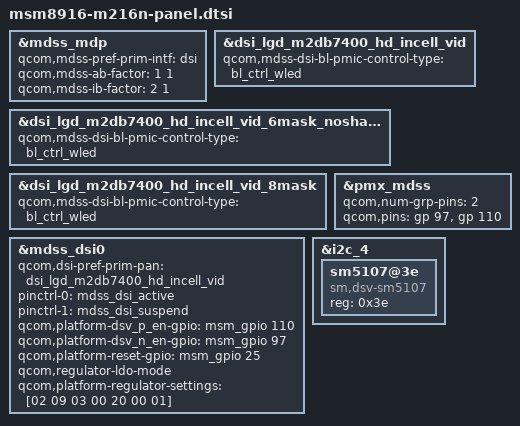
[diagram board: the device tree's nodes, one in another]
/* Copyright (c) 2013, Code Aurora Forum. All rights reserved.
 *
 * This program is free software; you can redistribute it and/or modify
 * it under the terms of the GNU General Public License version 2 and
 * only version 2 as published by the Free Software Foundation.
 *
 * This program is distributed in the hope that it will be useful,
 * but WITHOUT ANY WARRANTY; without even the implied warranty of
 * MERCHANTABILITY or FITNESS FOR A PARTICULAR PURPOSE.  See the
 * GNU General Public License for more details.
 */

#include "../msm8916-lge-common/dsi-panel-lgd-m2db7400-720p-video_m216n_kr.dtsi"

&mdss_mdp {
       qcom,mdss-pref-prim-intf = "dsi";
       qcom,mdss-ab-factor = <1 1>;
       qcom,mdss-ib-factor = <2 1>;
};

&dsi_lgd_m2db7400_hd_incell_vid {
       qcom,mdss-dsi-bl-pmic-control-type = "bl_ctrl_wled";
};

&dsi_lgd_m2db7400_hd_incell_vid_6mask_nosharp {
       qcom,mdss-dsi-bl-pmic-control-type = "bl_ctrl_wled";
};

&dsi_lgd_m2db7400_hd_incell_vid_8mask {
       qcom,mdss-dsi-bl-pmic-control-type = "bl_ctrl_wled";
};

&pmx_mdss {
	qcom,num-grp-pins = <2>;
	qcom,pins = <&gp 97>, <&gp 110>;
};

&mdss_dsi0 {
       qcom,dsi-pref-prim-pan = <&dsi_lgd_m2db7400_hd_incell_vid>;
       pinctrl-names = "mdss_default", "mdss_sleep";
       pinctrl-0 = <&mdss_dsi_active>;
       pinctrl-1 = <&mdss_dsi_suspend>;

       qcom,platform-dsv_p_en-gpio = <&msm_gpio 110 0>;
       qcom,platform-dsv_n_en-gpio = <&msm_gpio 97 0>;
	   /delete-property/ qcom,platform-bklight-en-gpio;
       qcom,platform-reset-gpio = <&msm_gpio 25 0>;
       qcom,regulator-ldo-mode;
       qcom,platform-regulator-settings = [02 09 03 00 20 00 01];

};

&i2c_4 {
	sm5107@3e {
		compatible = "sm,dsv-sm5107";
		status = "ok";
		reg = <0x3e>;
	};
};
